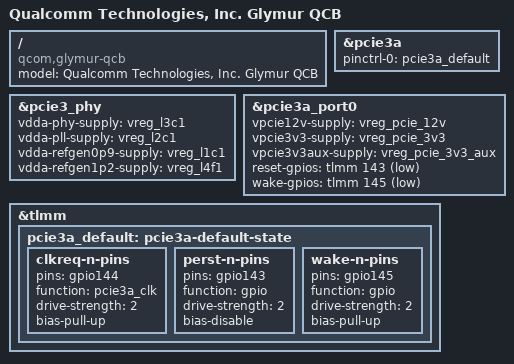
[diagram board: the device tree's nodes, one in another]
// SPDX-License-Identifier: BSD-3-Clause
/*
 * Copyright (c) Qualcomm Technologies, Inc. and/or its subsidiaries.
 */

/dts-v1/;

#include "glymur-cob.dtsi"
#include "glymur-qcb.dtsi"

/ {
	model = "Qualcomm Technologies, Inc. Glymur QCB";
	compatible = "qcom,glymur-qcb", "qcom,glymur";
};

&pcie3a {
	pinctrl-0 = <&pcie3a_default>;
	pinctrl-names = "default";

	status = "okay";
};

&pcie3_phy {
	vdda-phy-supply = <&vreg_l3c1>;
	vdda-pll-supply = <&vreg_l2c1>;
	vdda-refgen0p9-supply = <&vreg_l1c1>;
	vdda-refgen1p2-supply = <&vreg_l4f1>;

	status = "okay";
};

&pcie3a_port0 {
	vpcie12v-supply = <&vreg_pcie_12v>;
	vpcie3v3-supply = <&vreg_pcie_3v3>;
	vpcie3v3aux-supply = <&vreg_pcie_3v3_aux>;

	reset-gpios = <&tlmm 143 GPIO_ACTIVE_LOW>;
	wake-gpios = <&tlmm 145 GPIO_ACTIVE_LOW>;
};

&tlmm {
	pcie3a_default: pcie3a-default-state {
		clkreq-n-pins {
			pins = "gpio144";
			function = "pcie3a_clk";
			drive-strength = <2>;
			bias-pull-up;
		};

		perst-n-pins {
			pins = "gpio143";
			function = "gpio";
			drive-strength = <2>;
			bias-disable;
		};

		wake-n-pins {
			pins = "gpio145";
			function = "gpio";
			drive-strength = <2>;
			bias-pull-up;
		};
	};
};
